# GD32H71x_72x register map
File version: 1.0
CPU: CM7 r1p2, little endian, MPU, FPU, 4 interrupt priority bits
Registers are 32-bit, read-write, reset 0x0 unless marked. A register's access mark holds for its fields unless they carry their own. Offsets are from the block's base; [hi:lo] are bit positions; {n}, {i} and the like mark numbered series.

## BISS0 — BiSS-C encoder interface module
Base 0x4000D000
Same registers: BISS1 0x40002400
{0x0+8i} S{i}DATA0 (i=0..7) — BISS slave {i} data register 0
  [31:0] DATAL — Low double word process data of slave {i}.
{0x4+8i} S{i}DATA1 (i=0..7) — BISS slave {i} data register 1
  [31:0] DATAH — High double word process data of slave {i}.
{0x80+4i} CCDATA{i} (i=0..15) — BISS control communication data {i} regist
  [31:0] CCDATA — As storing the data of automatic register communication:
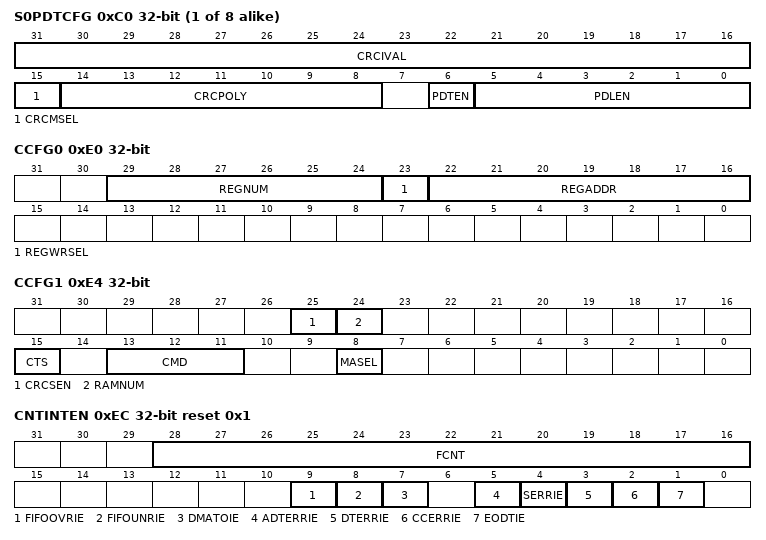
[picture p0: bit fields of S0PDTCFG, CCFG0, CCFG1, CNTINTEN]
{0xC0+4i} S{i}PDTCFG (i=0..7) — BISS slave n process data transmission configuration regist {i}
  [31:16] CRCIVAL — CRC calculation initial value
  [15] CRCMSEL — CRC polynomial mode selection
  [14:8] CRCPOLY — As prefined CRC polynomial:
  [6] PDTEN — Process data transmisson enable
  [5:0] PDLEN — Process data length
0xE0 CCFG0 — BISS communication configuration register 0
  [29:24] REGNUM — The number of consecutive communication registers in register communication mode
  [23] REGWRSEL — Register communication write/read mode selection
  [22:16] REGADDR — Register communication start address
0xE4 CCFG1 — BISS communication configuration register 1
  [25] CRCSEN — CRC storage enable
  [24] RAMNUM — Number of RAM banks used for process data
  [15] CTS — Control communication mode selection
  [13:11] CMD — As slave addressing for register communication:
  [8] MASEL — MA signal level selection at the end of frame.
0xE8 FREP reset 0xFFFFF — BISS frame repetition register
  [19:0] FREP — Frame automatic repetition rate
0xEC CNTINTEN reset 0x1 — BISS counter and interrupt enable register
  [28:16] FCNT — The count value from the BiSS frame's slave response ACK to the CDM timeout confirmation bit.
  [9] FIFOOVRIE — Interrupt enable of FIFOOVRIF
  [8] FIFOUNRIE — Interrupt enable of FIFOUNRIF
  [7] DMATOIE — Interrupt enable of DMATOIF
  [5] ADTERRIE — Interrupt enable of ADTERRIF
  [4] SERRIE — Interrupt enable of SERRIF
  [3] DTERRIE — Interrupt enable of DTERRF
  [2] CCERRIE — Interrupt enable of CCERRIF
  [1] EODTIE — Interrupt enable of EODTIF
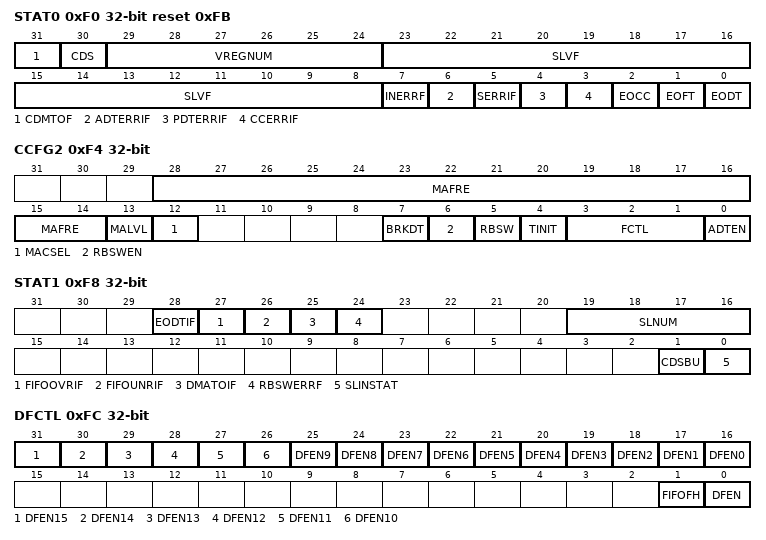
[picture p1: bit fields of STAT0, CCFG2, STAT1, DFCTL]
0xF0 STAT0 access per field reset 0xFB — BISS status register 0
  [31] CDMTOF ro — CDM timeout completion flag in control communication
  [30] CDS ro — CDS bit sent by slave
  [29:24] VREGNUM ro — Number of valid register from addressed slave in register communication
  [23:8] SLVF rw — Slave n data validity flag
  [7] INERRF ro — Internal error flag
  [6] ADTERRIF rw — Automatic data transmission error interrupt flag
  [5] SERRIF rw — Start bit error interrupt flag in register communication
  [4] PDTERRIF rw — Process data transmission error interrupt flag
  [3] CCERRIF rw — Control communication error interrupt flag
  [2] EOCC ro — End of control communication flag
  [1] EOFT ro — End of frame transmission flag
  [0] EODT ro — End of data transmission flag
0xF4 CCFG2 — BISS communication configuration register 2
  [28:14] MAFRE — Process data master clock frequency fMA
  [13] MALVL — MA line force level
  [12] MACSEL — MA line level control source selection
  [7] BRKDT — Break data transmission
  [6] RBSWEN — RAM bank automatic switching enable
  [5] RBSW — RAM bank force switching
  [4] TINIT — Transmit BiSS initialization sequence
  [3:1] FCTL — Frame control
  [0] ADTEN — Automatic data transmission enable
0xF8 STAT1 access per field — BISS status register 1
  [28] EODTIF rw — End of data transmission interrupt flag
  [27] FIFOOVRIF rw — FIFO overrun error interrupt flag
  [26] FIFOUNRIF rw — FIFO underrun error interrupt flag
  [25] DMATOIF rw — DMA request timeout error interrupt flag
  [24] RBSWERRF ro — RAM bank switching error flag
  [19:16] SLNUM ro — Number of slaves in control communication
  [1] CDSBU ro — CDS bit backup
  [0] SLINSTAT ro — SL line input level state
0xFC DFCTL access per field — BISS DMA and FIFO control register
  [31] DFEN15 rw — DMA request and FIFO enable for EDIM_BISS_S7RDATA1 register
  [30] DFEN14 rw — DMA request and FIFO enable for EDIM_BISS_S7RDATA0 register
  [29] DFEN13 rw — DMA request and FIFO enable for EDIM_BISS_S6RDATA1 register
  [28] DFEN12 rw — DMA request and FIFO enable for EDIM_BISS_S6RDATA0 register
  [27] DFEN11 rw — DMA request and FIFO enable for EDIM_BISS_S5RDATA1 register
  [26] DFEN10 rw — DMA request and FIFO enable for EDIM_BISS_S5RDATA0 register
  [25] DFEN9 rw — DMA request and FIFO enable for EDIM_BISS_S4RDATA1 register
  [24] DFEN8 rw — DMA request and FIFO enable for EDIM_BISS_S4RDATA0 register
  [23] DFEN7 rw — DMA request and FIFO enable for EDIM_BISS_S3RDATA1 register
  [22] DFEN6 rw — DMA request and FIFO enable for EDIM_BISS_S3RDATA0 register
  [21] DFEN5 rw — DMA request and FIFO enable for EDIM_BISS_S2RDATA1 register
  [20] DFEN4 rw — DMA request and FIFO enable for EDIM_BISS_S2RDATA0 register
  [19] DFEN3 rw — DMA request and FIFO enable for EDIM_BISS_S1RDATA1 register
  [18] DFEN2 rw — DMA request and FIFO enable for EDIM_BISS_S1RDATA0 register
  [17] DFEN1 rw — DMA request and FIFO enable for EDIM_BISS_S0RDATA1 register
  [16] DFEN0 rw — DMA request and FIFO enable for EDIM_BISS_S0RDATA0 register
  [1] FIFOFH wo — FIFO flush
  [0] DFEN rw — DMA request and FIFO enable
0x200 FIFODATA ro — BISS FIFO data register
  [31:0] FIFODATA — FIFO data from EDIM_BISS_SnDATA0_1 registers.
